# ipro6s register map
Vendor: intelpro; Series: IPRO6S
CPU: ipro6s, little endian
Registers are 32-bit, read-write, reset 0x0 unless marked. A register's access mark holds for its fields unless they carry their own. Offsets are from the block's base; [hi:lo] are bit positions.

## PDS
Base 0x3008E000
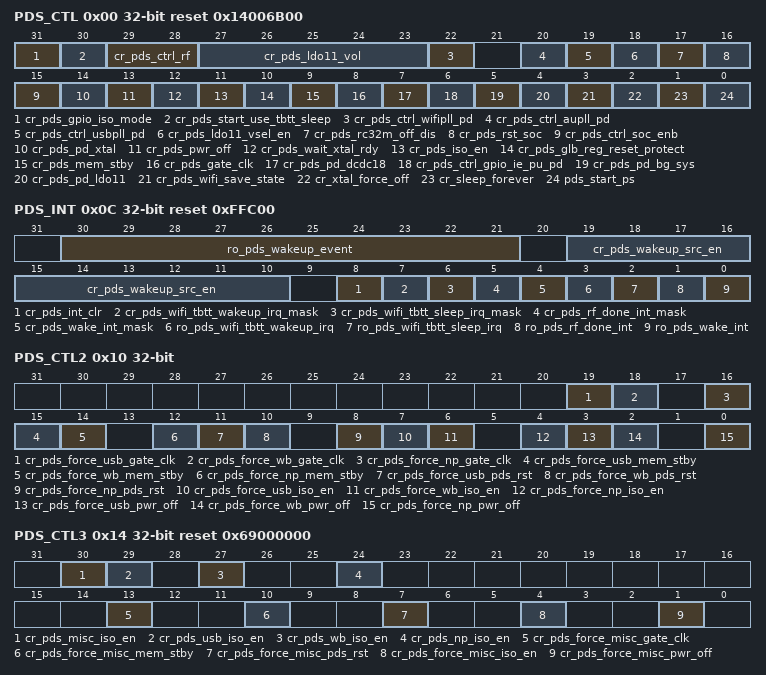
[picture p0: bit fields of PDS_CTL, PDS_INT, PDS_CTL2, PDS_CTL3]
0x00 PDS_CTL reset 0x14006B00
  [31] cr_pds_gpio_iso_mode — 1: HW Keep GPIO @ PDS7 0 : Clear this bit after PDS7 to release GPIO
  [30] cr_pds_start_use_tbtt_sleep — 1 : PDS Auto Sleep When wifi_tbtt_sleep_irq detect to 1 0 : don’t touch sleep
  [29:28] cr_pds_ctrl_rf — 00 : PDS don’t control RF on/off 01 : PDS control RF on/off depend on misc_pwr_off 10 : PDS control RF on/off depend on any power off 11 : PDS control RF on/off whe pds at idle state
  [27:23] cr_pds_ldo11_vol — LDO11 voltage value in PDS mode output voltage sel: 0: 0.9V, 4: 1.0V, 8: 1.1V, 12: 1.2V, 25mV/step
  [22] cr_pds_ctrl_wifipll_pd — PDS Control WIFI PLL off When pds_pwr_off
  [20] cr_pds_ctrl_aupll_pd — PDS Control Audio PLL off When pds_pwr_off
  [19] cr_pds_ctrl_usbpll_pd — PDS Control USB PLL off When pds_pwr_off
  [18] cr_pds_ldo11_vsel_en — PDS "SLEEP" control LDO11 voltage enable
  [17] cr_pds_rc32m_off_dis — 1 : RC32M always on @any state 0 : RC32M on/off controlled by PDS state
  [16] cr_pds_rst_soc — 0 : no pds_reset 1: pds_rst controlled by PDS
  [15] cr_pds_ctrl_soc_enb — 1 :pds_soc_enb controlled by PDS 0 :pds_soc_enb always active
  [14] cr_pds_pd_xtal — 0 : don’t_touch xtal during PDS 1 : xtal power down during PDS
  [13] cr_pds_pwr_off — 0 : don’t_touch Power during PDS 1 : Power off during PDS (each power domain can has its own control)
  [12] cr_pds_wait_xtal_rdy — 0 : Skip wait XTAL Ready before PDS Interrupt 1 : wait XTAL Ready during before PDS Interrupt
  [11] cr_pds_iso_en — 0 : don’t_touch Isolation during PDS (all power domain) 1 : Isolation during PDS (each power domain can has its own control)
  [10] cr_pds_glb_reg_reset_protect — 1: avoid glb_reg reset by any reset
  [9] cr_pds_mem_stby — 0 : don’t_touch mem_stby during PDS 1 : mem_stby during PDS (each power domain can has its own control)
  [8] cr_pds_gate_clk — 0 : don’t_touch clock gating during PDS (all power domain) 1 : gate clock during PDS (each pwr domain has its own control)
  [7] cr_pds_pd_dcdc18 — 0 : don’t_touch dcdc18 during PDS 1 : power down dcdc18 during PDS
  [6] cr_pds_ctrl_gpio_ie_pu_pd — 1: allow PDS Control the GPIO IE/PU/PD at Sleep Mode
  [5] cr_pds_pd_bg_sys — 0 : don’t_touch bg_sys during PDS 1 : power down bg_sys during PDS
  [4] cr_pds_pd_ldo11 — 0 : don’t_touch ldo11 during PDS 1 : power down ldo11 during PDS
  [3] cr_pds_wifi_save_state — Save WIFI State Before Enter PDS
  [2] cr_xtal_force_off
  [1] cr_sleep_forever
  [0] pds_start_ps wo — Enter PDS
0x04 PDS_TIME1 reset 0xCA8
  [31:0] cr_sleep_duration — PDS Sleep Time (in units of 32K clock cycles)
0x0C PDS_INT reset 0xFFC00 (reset mask 0xFFDF0)
  [30:21] ro_pds_wakeup_event ro — Record Wakeup resason, and be clear by cr_pds_int_clr [30]: wakeup trigger by wifi_tbtt_wakeup_irq [29] :wakeup trigger by usbh_conn_det_n [28]: wakeup trigger by usbh_wkp_det_n [27]: wakeup trigger by dm_slp_irq [26]: wakeup trigger by WIFI wakeup event [25]: wakeup trigger by irrx_int [24]: wakeup trigger by pds_gpio_int [23]: wakeup trigger by gpio_irq [22]: wakeup trigger by hbn_irq_out[1:0] [21]: wakeup trigger by pds_sleep_cnt=0
  [19:10] cr_pds_wakeup_src_en — PDS Wakeup Trigger [19]: enable wakeup trigger by wifi_tbtt_wakeup_irq [18] : enable wakeup trigger by usbh_conn_det_n [17]: enable wakeup trigger by usbh_wkp_det_n [16]: enable wakeup trigger by dm_slp_irq [15]: enable wakeup trigger by WIFI wakeup event [14]: enable wakeup trigger by irrx_int [13]: enable wakeup trigger by pds_gpio_int [12]: enable wakeup trigger by gpio_irq [11]: enable wakeup trigger by |hbn_irq_out[1:0] [10]: enable wakeup trigger by pds_sleep_cnt=0
  [8] cr_pds_int_clr — pds interrupt clear
  [7] cr_pds_wifi_tbtt_wakeup_irq_mask — Mask wifi_tbtt_wakeup_irq interrupt
  [6] cr_pds_wifi_tbtt_sleep_irq_mask — Mask wifi_tbtt_sleep_irq interrupt
  [5] cr_pds_rf_done_int_mask — Mask pds rf done interrupt
  [4] cr_pds_wake_int_mask — Mask pds wakeup interrupt
  [3] ro_pds_wifi_tbtt_wakeup_irq ro — wifi_tbtt_wakeup_irq
  [2] ro_pds_wifi_tbtt_sleep_irq ro — wifi_tbtt_sleep_irq
  [1] ro_pds_rf_done_int ro — pu_rf_done interrupt
  [0] ro_pds_wake_int ro — PDS Wakeup Interrupt
0x10 PDS_CTL2
  [19] cr_pds_force_usb_gate_clk — manual force usbio clock gated
  [18] cr_pds_force_wb_gate_clk — manual force WB clock gated
  [16] cr_pds_force_np_gate_clk — manual force NP clock gated
  [15] cr_pds_force_usb_mem_stby — manual force usbio memory sleep
  [14] cr_pds_force_wb_mem_stby — manual force WB memory sleep
  [12] cr_pds_force_np_mem_stby — manual force NP memory sleep
  [11] cr_pds_force_usb_pds_rst — manual force usbio pds reset
  [10] cr_pds_force_wb_pds_rst — manual force WB pds reset
  [8] cr_pds_force_np_pds_rst — manual force NP pds reset
  [7] cr_pds_force_usb_iso_en — manual force usbio isolation
  [6] cr_pds_force_wb_iso_en — manual force WB isolation
  [4] cr_pds_force_np_iso_en — manual force NP isolation
  [3] cr_pds_force_usb_pwr_off — manual force usbio power off
  [2] cr_pds_force_wb_pwr_off — manual force WB power off
  [0] cr_pds_force_np_pwr_off — manual force NP power off
0x14 PDS_CTL3 reset 0x69000000
  [30] cr_pds_misc_iso_en — 1 : make misc isolated at PDS Sleep state 0 : make misc isolated at PDS Sleep state
  [29] cr_pds_usb_iso_en — 1 : make usb isolated at PDS Sleep state 0 : make usb isolated at PDS Sleep state
  [27] cr_pds_wb_iso_en — 1 : make WB isolated at PDS Sleep state 0 : make WB isolated at PDS Sleep state
  [24] cr_pds_np_iso_en — 1 : make NP isolated at PDS Sleep state 0 : make NP isolated at PDS Sleep state
  [13] cr_pds_force_misc_gate_clk — manual force MISC gate_clk
  [10] cr_pds_force_misc_mem_stby — manual force MISC mem_stby
  [7] cr_pds_force_misc_pds_rst — manual force MISC pds_rst
  [4] cr_pds_force_misc_iso_en — manual force MISC iso_en
  [1] cr_pds_force_misc_pwr_off — manual force MISC pwr_off
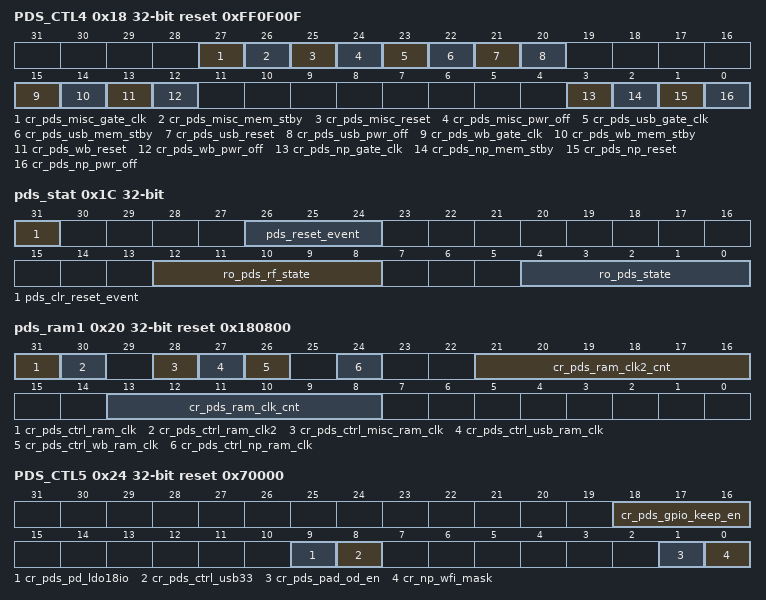
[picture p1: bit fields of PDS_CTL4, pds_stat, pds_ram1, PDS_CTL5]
0x18 PDS_CTL4 reset 0xFF0F00F
  [27] cr_pds_misc_gate_clk — 1 : make core_misc clock gated at PDS Sleep state 0 : make core_misc clocking at PDS Sleep state
  [26] cr_pds_misc_mem_stby — 1 : make core_misc RAM @Retention at PDS Sleep state 0 : make core_misc RAM @ Normal at PDS Sleep state
  [25] cr_pds_misc_reset — 1 : make core_misc reset at PDS Sleep state 0 : make core_misc not reset at PDS Sleep state
  [24] cr_pds_misc_pwr_off — 1 : make core_misc Power off at PDS Sleep state 0 : make core_misc power on at PDS Sleep state
  [23] cr_pds_usb_gate_clk — 1 : make usb clock gated at PDS Sleep state 0 : make usb clocking at PDS Sleep state
  [22] cr_pds_usb_mem_stby — 1 : make usb RAM @Retention at PDS Sleep state 0 : make usb RAM @ Normal at PDS Sleep state
  [21] cr_pds_usb_reset — 1 : make usb reset at PDS Sleep state 0 : make usb not reset at PDS Sleep state
  [20] cr_pds_usb_pwr_off — 1 : make usb Power off at PDS Sleep state 0 : make usb power on at PDS Sleep state
  [15] cr_pds_wb_gate_clk — 1 : make WB clock gated at PDS Sleep state 0 : make WB clocking at PDS Sleep state
  [14] cr_pds_wb_mem_stby — 1 : make WB RAM @Retention at PDS Sleep state 0 : make WB RAM @ Normal at PDS Sleep state
  [13] cr_pds_wb_reset — 1 : make WB reset at PDS Sleep state 0 : make WB not reset at PDS Sleep state
  [12] cr_pds_wb_pwr_off — 1 : make WB Power off at PDS Sleep state 0 : make WB power on at PDS Sleep state
  [3] cr_pds_np_gate_clk — 1 : make NP clock gated at PDS Sleep state 0 : make NP clocking at PDS Sleep state
  [2] cr_pds_np_mem_stby — 1 : make NP RAM @Retention at PDS Sleep state 0 : make NP RAM @ Normal at PDS Sleep state
  [1] cr_pds_np_reset — 1 : make NP reset at PDS Sleep state 0 : make NP not reset at PDS Sleep state
  [0] cr_pds_np_pwr_off — 1 : make NP Power off at PDS Sleep state 0 : make NP power on at PDS Sleep state
0x1C pds_stat (reset mask 0x80000000)
  [31] pds_clr_reset_event wo — clear pds reset event
  [26:24] pds_reset_event ro — [2] : pds_rst_n (pds reset) [1]: pwr_rst_n (hbn power on reset) [0]: hreset_n (Bus Reset)
  [12:8] ro_pds_rf_state ro — ST_PDS_RF_OFF = 5'b0000 ; ST_PDS_PU_MBG = 5'b0001 ; ST_PDS_PU_LDO15RF = 5'b0011 ; ST_PDS_PU_SFREG = 5'b0111 ; ST_PDS_PUD_XTAL18 = 5'b01111; ST_PDS_WB_EN_AON = 5'b11111 ;
  [4:0] ro_pds_state ro — ST_IDLE = 5'b00000; ST_MEM_STBY = 5'b10000; ST_ECG = 5'b01000; ST_ERST = 5'b01100; ST_EISO = 5'b01111; ST_POFF = 5'b00111; ST_PRE_BGON = 5'b00011; ST_PRE_BGON1 = 5'b00001; ST_BGON = 5'b00101; ST_CLK_SW_32M= 5'b00100; ST_PON_DCDC = 5'b00110; ST_PON_LDO11_MISC = 5'b01110; ST_PON = 5'b01010; ST_DISO = 5'b00010; ST_DCG = 5'b01101; ST_MEM_IDLE = 5'b11000; ST_DRST = 5'b01011; ST_WAIT_EFUSE= 5'b01001;
0x20 pds_ram1 reset 0x180800
  [31] cr_pds_ctrl_ram_clk — 1 : Enable PDS Control PD_CORE SRAM Clock @ PDS Sequence
  [30] cr_pds_ctrl_ram_clk2 — HW Option To assert extra clock during PDS on sequence
  [28] cr_pds_ctrl_misc_ram_clk — This bit is Enable by bit [31] : cr_pds_ctrl_ram_clk 1 : PDS Control PD_CORE_MISC SRAM Clock @ PDS Sequence 0 : PDS do nothing on SRAM Clock
  [27] cr_pds_ctrl_usb_ram_clk — This bit is Enable by bit [31] : cr_pds_ctrl_ram_clk 1 : PDS Control PD_usb SRAM Clock @ PDS Sequence 0 : PDS do nothing on PD_usb SRAM Clock
  [26] cr_pds_ctrl_wb_ram_clk — This bit is Enable by bit [31] : cr_pds_ctrl_ram_clk 1 : PDS Control PD_WB SRAM Clock @ PDS Sequence 0 : PDS do nothing on PD_WB SRAM Clock
  [24] cr_pds_ctrl_np_ram_clk — This bit is Enable by bit [31] : cr_pds_ctrl_ram_clk 1 : PDS Control PD_CORE_CPU SRAM Clock @ PDS Sequence 0 : PDS do nothing on PD_CORE_CPU SRAM Clock
  [21:16] cr_pds_ram_clk2_cnt — HW Option : Assert Extra Clock Counter in MEM_IDLE
  [13:8] cr_pds_ram_clk_cnt — HW Option : Assert Extra Clock Counter in MEM_STBY
0x24 PDS_CTL5 reset 0x70000
  [18:16] cr_pds_gpio_keep_en — if cr_pds_gpio_iso_mode=1, can use bit to enable or disable keep function [0] : GPIO0~15 [1] : GPIO20~36 (not include GPIO21/22/28/29) [2] : GPIO16~19
  [9] cr_pds_pd_ldo18io — 0 : don’t_touch ldo18io during PDS 1 : power down ldo18io during PDS
  [8] cr_pds_ctrl_usb33 — Set this bit to enable HW control turn on/off USB 3.3V @USB1.1V Power On/OFF (Replace the function of reg_pu_usb20_psw)
  [1] cr_pds_pad_od_en — GPIO21/22/28/29 5V Tolerant PAD Open Drain Enable
  [0] cr_np_wfi_mask — pds start condition mask np_wfi
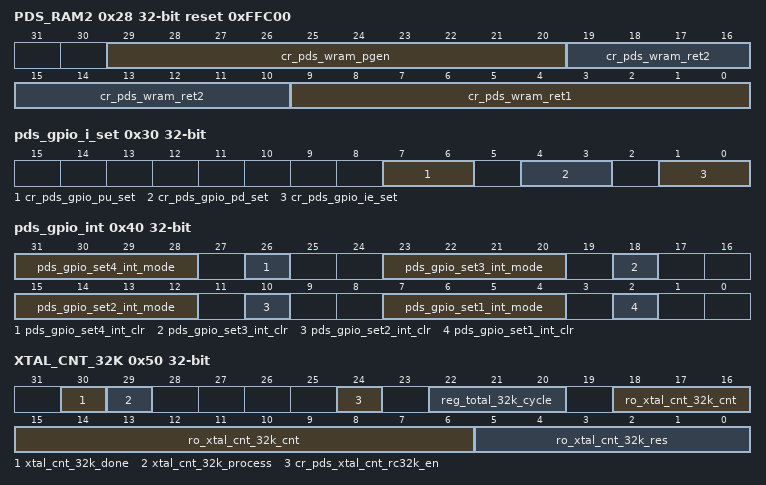
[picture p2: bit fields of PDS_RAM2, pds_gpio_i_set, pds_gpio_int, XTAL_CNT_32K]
0x28 PDS_RAM2 reset 0xFFC00
  [29:20] cr_pds_wram_pgen — [9] : 144~160KB WRAM PGEN [8] : 128~144KB WRAM PGEN [7] : 112~128KB WRAM PGEN [6] : 96~112KB WRAM PGEN [5] : 80~96KB WRAM PGEN [4] : 64~80KB WRAM PGEN [3] : 48~64KB WRAM PGEN [2] : 32~48KB WRAM PGEN [1] : 16~32KB WRAM PGEN [0] : 0~16KB WRAM PGEN
  [19:10] cr_pds_wram_ret2 — [9] : 144~160KB WRAM RET2 [8] : 128~144KB WRAM RET2 [7] : 112~128KB WRAM RET2 [6] : 96~112KB WRAM RET2 [5] : 80~96KB WRAM RET2 [4] : 64~80KB WRAM RET2 [3] : 48~64KB WRAM RET2 [2] : 32~48KB WRAM RET2 [1] : 16~32KB WRAM RET2 [0] : 0~16KB WRAM RET2
  [9:0] cr_pds_wram_ret1 — [9] : 144~160KB WRAM RET1 [8] : 128~144KB WRAM RET1 [7] : 112~128KB WRAM RET1 [6] : 96~112KB WRAM RET1 [5] : 80~96KB WRAM RET1 [4] : 64~80KB WRAM RET1 [3] : 48~64KB WRAM RET1 [2] : 32~48KB WRAM RET1 [1] : 16~32KB WRAM RET1 [0] : 0~16KB WRAM RET1
0x30 pds_gpio_i_set
  [7:6] cr_pds_gpio_pu_set — Enable GPIO PU @ PDS [0] : GPIO0~15 [1] : GPIO20~36
  [4:3] cr_pds_gpio_pd_set — Enable GPIO PD @ PDS [0] : GPIO0~15 [1] : GPIO20~36
  [1:0] cr_pds_gpio_ie_set — Enable GPIO IE @ PDS [0] : GPIO0~15 [1] : GPIO20~36
0x34 pds_gpio_pd_set reset 0x7FFFFFFF
  [30:0] cr_pds_gpio_set_int_mask — PDS Interrupt Mask for GPIO [0] GPIO0 [1] GPIO1 [2] GPIO2 [3] GPIO3 [4] GPIO4 [5] GPIO5 [6] GPIO6 [7] GPIO7 [8] GPIO8 [9] GPIO9 [10] GPIO10 [11] GPIO11 [12] GPIO12 [13] GPIO13 [14] GPIO14 [15] GPIO15 [16] GPIO20 [17] GPIO21 [18] GPIO22 [19] GPIO23 [20] GPIO24 [21] GPIO25 [22] GPIO26 [23] GPIO27 [24] GPIO28 [25] GPIO29 [26] GPIO30 [27] GPIO31 [28] GPIO32 [29] GPIO33 [30] GPIO34
0x40 pds_gpio_int
  [31:28] pds_gpio_set4_int_mode — GPIO28~34 PDS Interrupt Mode 0000 : sync falling edge trigger 0001 : sync rising edge trigger 0010 : sync low level trigger 0011 : sync high level trigger 01xx : sync rising & falling edge trigger 1000 : async falling edge trigger 1001 : async rising edge trigger 1010 : async low level trigger 1011 : async high level trigger
  [26] pds_gpio_set4_int_clr — Clear GPIO28~34 PDS IO Interrupt
  [23:20] pds_gpio_set3_int_mode — GPIO20~27 PDS Interrupt Mode 0000 : sync falling edge trigger 0001 : sync rising edge trigger 0010 : sync low level trigger 0011 : sync high level trigger 01xx : sync rising & falling edge trigger 1000 : async falling edge trigger 1001 : async rising edge trigger 1010 : async low level trigger 1011 : async high level trigger
  [18] pds_gpio_set3_int_clr — Clear GPIO20~27 PDS IO Interrupt
  [15:12] pds_gpio_set2_int_mode — GPIO8~15 PDS Interrupt Mode 0000 : sync falling edge trigger 0001 : sync rising edge trigger 0010 : sync low level trigger 0011 : sync high level trigger 01xx : sync rising & falling edge trigger 1000 : async falling edge trigger 1001 : async rising edge trigger 1010 : async low level trigger 1011 : async high level trigger
  [10] pds_gpio_set2_int_clr — Clear GPIO8~15 PDS IO Interrupt
  [7:4] pds_gpio_set1_int_mode — GPIO0~7 PDS Interrupt Mode 0000 : sync falling edge trigger 0001 : sync rising edge trigger 0010 : sync low level trigger 0011 : sync high level trigger 01xx : sync rising & falling edge trigger 1000 : async falling edge trigger 1001 : async rising edge trigger 1010 : async low level trigger 1011 : async high level trigger
  [2] pds_gpio_set1_int_clr — Clear GPIO0~7 PDS IO Interrupt
0x44 pds_gpio_stat reset not defined
  [30:0] pds_gpio_int_stat ro
0x48 PDS_RAM3 reset 0xFFFFF
  [19:0] cr_pds_ocram_ret2 — [19] : 304~320KB OCRAM RET2 [18] : 288~304KB OCRAM RET2 [17] : 272~288KB OCRAM RET2 [16] : 256~272KB OCRAM RET2 [15] : 240~256KB OCRAM RET2 [14] : 224~240KB OCRAM RET2 [13] : 208~224KB OCRAM RET2 [12] : 192~208KB OCRAM RET2 [11] : 176~192KB OCRAM RET2 [10] : 160~176KB OCRAM RET2 [9] : 144~160KB OCRAM RET2 [8] : 128~144KB OCRAM RET2 [7] : 112~128KB OCRAM RET2 [6] : 96~112KB OCRAM RET2 [5] : 80~96KB OCRAM RET2 [4] : 64~80KB OCRAM RET2 [3] : 48~64KB OCRAM RET2 [2] : 32~48KB OCRAM RET2 [1] : 16~32KB OCRAM RET2 [0] : 0~16KB OCRAM RET2
0x4C PDS_RAM4
  [19:0] cr_pds_ocram_ret1 — [19] : 304~320KB OCRAM RET1 [18] : 288~304KB OCRAM RET1 [17] : 272~288KB OCRAM RET1 [16] : 256~272KB OCRAM RET1 [15] : 240~256KB OCRAM RET1 [14] : 224~240KB OCRAM RET1 [13] : 208~224KB OCRAM RET1 [12] : 192~208KB OCRAM RET1 [11] : 176~192KB OCRAM RET1 [10] : 160~176KB OCRAM RET1 [9] : 144~160KB OCRAM RET1 [8] : 128~144KB OCRAM RET1 [7] : 112~128KB OCRAM RET1 [6] : 96~112KB OCRAM RET1 [5] : 80~96KB OCRAM RET1 [4] : 64~80KB OCRAM RET1 [3] : 48~64KB OCRAM RET1 [2] : 32~48KB OCRAM RET1 [1] : 16~32KB OCRAM RET1 [0] : 0~16KB OCRAM RET1
0x50 XTAL_CNT_32K (reset mask 0x1700000)
  [30] xtal_cnt_32k_done ro — also to IRQ[33]
  [29] xtal_cnt_32k_process ro
  [24] cr_pds_xtal_cnt_rc32k_en — 1: HW Auto count RC32K to be XTAL Counter after PDS
  [22:20] reg_total_32k_cycle — Average of 32K Cycle 4~7: 64 Cycle 3 : 32 Cycle 2 : 16 Cycle 1 : 8 Cycle 0 : 4 Cycle
  [18:6] ro_xtal_cnt_32k_cnt ro — Average 32K in XTAL CNT Cycle
  [5:0] ro_xtal_cnt_32k_res ro — Residue of XTAL Cycle Corresponding to reg_total_32_cycle xtal_cnt_32k_res in units of 1/64 XTAL Cycle
0x54 PDS_RAM5
  [19:0] cr_pds_ocram_pgen — [19] : 304~320KB OCRAM PGEN [18] : 288~304KB OCRAM PGEN [17] : 272~288KB OCRAM PGEN [16] : 256~272KB OCRAM PGEN [15] : 240~256KB OCRAM PGEN [14] : 224~240KB OCRAM PGEN [13] : 208~224KB OCRAM PGEN [12] : 192~208KB OCRAM PGEN [11] : 176~192KB OCRAM PGEN [10] : 160~176KB OCRAM PGEN [9] : 144~160KB OCRAM PGEN [8] : 128~144KB OCRAM PGEN [7] : 112~128KB OCRAM PGEN [6] : 96~112KB OCRAM PGEN [5] : 80~96KB OCRAM PGEN [4] : 64~80KB OCRAM PGEN [3] : 48~64KB OCRAM PGEN [2] : 32~48KB OCRAM PGEN [1] : 16~32KB OCRAM PGEN [0] : 0~16KB OCRAM PGEN
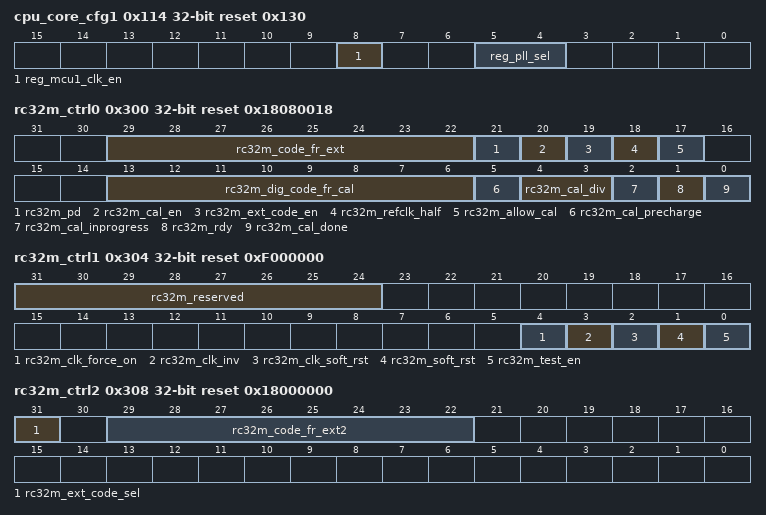
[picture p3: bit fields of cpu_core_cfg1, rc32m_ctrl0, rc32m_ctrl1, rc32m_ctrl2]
0x114 cpu_core_cfg1 reset 0x130
  [8] reg_mcu1_clk_en
  [5:4] reg_pll_sel — pll clock selection for fclk (0:AUPLL_DIV2_CLK, 1: AUPLL_DIV1_CLK 2: WIFIPLL_240MHz 3: WIFIPLL_320MHz)
0x148 cpu_core_cfg14 reset 0x10FE0000
  [31:0] e906_rst_addr
0x300 rc32m_ctrl0 reset 0x18080018 (reset mask 0x3FFE0018)
  [29:22] rc32m_code_fr_ext — External code In for frequency setting
  [21] rc32m_pd — Power down 32m oscillator
  [20] rc32m_cal_en — Enable calibration of 32m oscillator
  [19] rc32m_ext_code_en — Allow external code in to go into the ckt
  [18] rc32m_refclk_half — reference clock select 32M or 64M
  [17] rc32m_allow_cal — Allow calibration to be performed (monitor system clock)
  [13:6] rc32m_dig_code_fr_cal ro — After calibration hold calibrated code
  [5] rc32m_cal_precharge ro — Initial a new cal
  [4:3] rc32m_cal_div — Divider for the clock step during calibration
  [2] rc32m_cal_inprogress ro — Asserts high when calibration is in progress
  [1] rc32m_rdy ro — Asserts high when 32k clock is ready upon pwrup
  [0] rc32m_cal_done ro — Asserts high when calibration is done
0x304 rc32m_ctrl1 reset 0xF000000
  [31:24] rc32m_reserved — rc32m_reserved[31]=ldo28cis_rc_dec_opt
  [4] rc32m_clk_force_on — Bypass the clock gating if set to 1'h1
  [3] rc32m_clk_inv — Digital clock inverted or not: 1'h0 Buffered clock. 1'h1 Inverted clock.
  [2] rc32m_clk_soft_rst — soft reset for clk divider
  [1] rc32m_soft_rst — soft reset
  [0] rc32m_test_en — dc test enable
0x308 rc32m_ctrl2 reset 0x18000000
  [31] rc32m_ext_code_sel — 0: load from rc32m_code_fr_ext; 1:load form rc32m_code_fr_ext2 with pds_clk_gate
  [29:22] rc32m_code_fr_ext2 — External code2 In for frequency setting
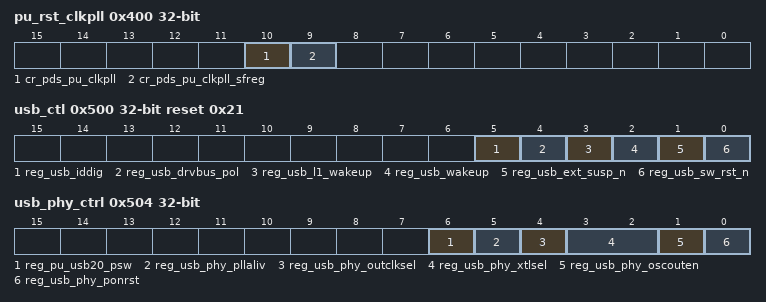
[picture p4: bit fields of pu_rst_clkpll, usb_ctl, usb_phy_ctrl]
0x400 pu_rst_clkpll
  [10] cr_pds_pu_clkpll — PDS Software PU CKPLL
  [9] cr_pds_pu_clkpll_sfreg — PDS Software PU clock PLL source follow regular
0x500 usb_ctl reset 0x21
  [5] reg_usb_iddig — OTG ID indicator 0: Device-A 1: Device-B
  [4] reg_usb_drvbus_pol — VBUS charge pump enable polarity 0: NOT inversed, active high 1: Inversed, active low
  [3] reg_usb_l1_wakeup — The L1 remote wakeup invoked by application. This signal is used only when FOTG210 operates in the device mode. If this signal is asserted while FOTG210 is in L1 state, FOTG210 would start resuming and exit from L1 state.
  [2] reg_usb_wakeup — The remote L2 wakeup invoked by application. This signal is used only when FOTG210 operates in the device mode.
  [1] reg_usb_ext_susp_n — Active-low suspend signal
  [0] reg_usb_sw_rst_n — Active-low reset signal
0x504 usb_phy_ctrl
  [6] reg_pu_usb20_psw — 1: rf808_usb20_psw_rref output 3.3V power 0 :rf808_usb20_psw_rref output off
  [5] reg_usb_phy_pllaliv — PLL alive
  [4] reg_usb_phy_outclksel — Reference clock selection 0: Reference clock from XTALIN 1: Reference clock from CORECLKIN
  [3:2] reg_usb_phy_xtlsel — Reference clock frequence selection 00: 12-MHz input reference clock 01: 30-MHz input reference clock 1X: Reserved
  [1] reg_usb_phy_oscouten — CLKOSCO clock output enable
  [0] reg_usb_phy_ponrst — Active-low reset signal
